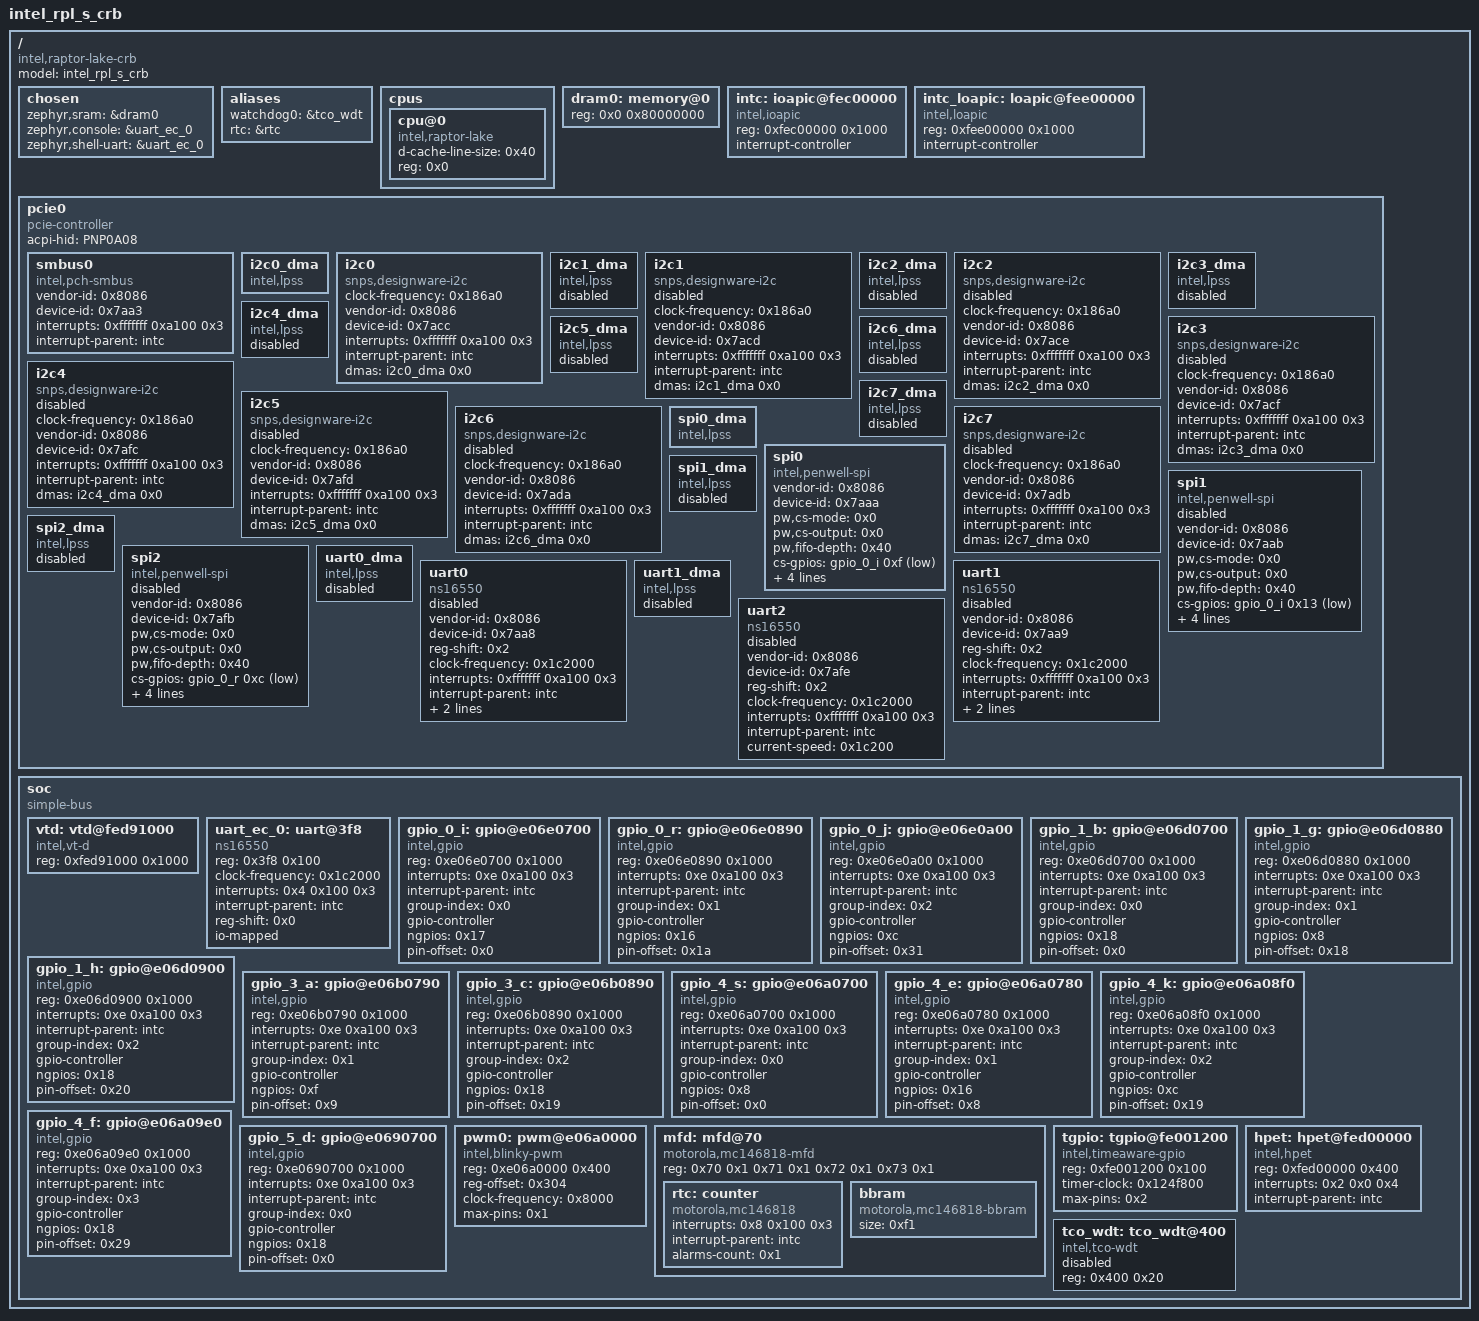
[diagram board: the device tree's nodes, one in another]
/dts-v1/;

/* node '/' defined in zephyr/dts/common/skeleton.dtsi:9 */
/ {
	#address-cells = < 0x1 >;             /* in zephyr/dts/common/skeleton.dtsi:10 */
	#size-cells = < 0x1 >;                /* in zephyr/dts/common/skeleton.dtsi:11 */
	model = "intel_rpl_s_crb";            /* in zephyr/boards/intel/rpl/intel_rpl_s_crb.dts:15 */
	compatible = "intel,raptor-lake-crb"; /* in zephyr/boards/intel/rpl/intel_rpl_s_crb.dts:16 */

	/* node '/chosen' defined in zephyr/dts/common/skeleton.dtsi:13 */
	chosen {
		zephyr,sram = &dram0;           /* in zephyr/boards/intel/rpl/intel_rpl_s_crb.dts:19 */
		zephyr,console = &uart_ec_0;    /* in zephyr/boards/intel/rpl/intel_rpl_s_crb.dts:20 */
		zephyr,shell-uart = &uart_ec_0; /* in zephyr/boards/intel/rpl/intel_rpl_s_crb.dts:21 */
	};

	/* node '/aliases' defined in zephyr/dts/common/skeleton.dtsi:15 */
	aliases {
		watchdog0 = &tco_wdt; /* in zephyr/boards/intel/rpl/intel_rpl_s_crb.dts:25 */
		rtc = &rtc;           /* in zephyr/boards/intel/rpl/intel_rpl_s_crb.dts:26 */
	};

	/* node '/cpus' defined in zephyr/dts/x86/intel/raptor_lake_s.dtsi:13 */
	cpus {
		#address-cells = < 0x1 >; /* in zephyr/dts/x86/intel/raptor_lake_s.dtsi:14 */
		#size-cells = < 0x0 >;    /* in zephyr/dts/x86/intel/raptor_lake_s.dtsi:15 */

		/* node '/cpus/cpu@0' defined in zephyr/dts/x86/intel/raptor_lake_s.dtsi:17 */
		cpu@0 {
			device_type = "cpu";              /* in zephyr/dts/x86/intel/raptor_lake_s.dtsi:18 */
			compatible = "intel,raptor-lake",
			             "intel,x86_64";      /* in zephyr/dts/x86/intel/raptor_lake_s.dtsi:19 */
			d-cache-line-size = < 0x40 >;     /* in zephyr/dts/x86/intel/raptor_lake_s.dtsi:20 */
			reg = < 0x0 >;                    /* in zephyr/dts/x86/intel/raptor_lake_s.dtsi:21 */
		};
	};

	/* node '/memory@0' defined in zephyr/dts/x86/intel/raptor_lake_s.dtsi:25 */
	dram0: memory@0 {
		device_type = "memory";   /* in zephyr/dts/x86/intel/raptor_lake_s.dtsi:26 */
		reg = < 0x0 0x80000000 >; /* in zephyr/dts/x86/intel/raptor_lake_s.dtsi:27 */
	};

	/* node '/ioapic@fec00000' defined in zephyr/dts/x86/intel/raptor_lake_s.dtsi:30 */
	intc: ioapic@fec00000 {
		compatible = "intel,ioapic"; /* in zephyr/dts/x86/intel/raptor_lake_s.dtsi:31 */
		#address-cells = < 0x1 >;    /* in zephyr/dts/x86/intel/raptor_lake_s.dtsi:32 */
		#interrupt-cells = < 0x3 >;  /* in zephyr/dts/x86/intel/raptor_lake_s.dtsi:33 */
		reg = < 0xfec00000 0x1000 >; /* in zephyr/dts/x86/intel/raptor_lake_s.dtsi:34 */
		interrupt-controller;        /* in zephyr/dts/x86/intel/raptor_lake_s.dtsi:35 */
		phandle = < 0x1 >;           /* in zephyr/dts/x86/intel/raptor_lake_s.dtsi:60 */
	};

	/* node '/loapic@fee00000' defined in zephyr/dts/x86/intel/raptor_lake_s.dtsi:38 */
	intc_loapic: loapic@fee00000 {
		compatible = "intel,loapic"; /* in zephyr/dts/x86/intel/raptor_lake_s.dtsi:39 */
		reg = < 0xfee00000 0x1000 >; /* in zephyr/dts/x86/intel/raptor_lake_s.dtsi:40 */
		interrupt-controller;        /* in zephyr/dts/x86/intel/raptor_lake_s.dtsi:41 */
		#interrupt-cells = < 0x3 >;  /* in zephyr/dts/x86/intel/raptor_lake_s.dtsi:42 */
		#address-cells = < 0x1 >;    /* in zephyr/dts/x86/intel/raptor_lake_s.dtsi:43 */
	};

	/* node '/pcie0' defined in zephyr/dts/x86/intel/raptor_lake_s.dtsi:46 */
	pcie0: pcie0 {
		#address-cells = < 0x1 >;       /* in zephyr/dts/x86/intel/raptor_lake_s.dtsi:47 */
		#size-cells = < 0x1 >;          /* in zephyr/dts/x86/intel/raptor_lake_s.dtsi:48 */
		compatible = "pcie-controller"; /* in zephyr/dts/x86/intel/raptor_lake_s.dtsi:49 */
		acpi-hid = "PNP0A08";           /* in zephyr/dts/x86/intel/raptor_lake_s.dtsi:50 */
		ranges;                         /* in zephyr/dts/x86/intel/raptor_lake_s.dtsi:51 */

		/* node '/pcie0/smbus0' defined in zephyr/dts/x86/intel/raptor_lake_s.dtsi:53 */
		smbus0: smbus0 {
			compatible = "intel,pch-smbus";        /* in zephyr/dts/x86/intel/raptor_lake_s.dtsi:54 */
			#address-cells = < 0x1 >;              /* in zephyr/dts/x86/intel/raptor_lake_s.dtsi:55 */
			#size-cells = < 0x0 >;                 /* in zephyr/dts/x86/intel/raptor_lake_s.dtsi:56 */
			vendor-id = < 0x8086 >;                /* in zephyr/dts/x86/intel/raptor_lake_s.dtsi:57 */
			device-id = < 0x7aa3 >;                /* in zephyr/dts/x86/intel/raptor_lake_s.dtsi:58 */
			interrupts = < 0xfffffff 0xa100 0x3 >; /* in zephyr/dts/x86/intel/raptor_lake_s.dtsi:59 */
			interrupt-parent = < &intc >;          /* in zephyr/dts/x86/intel/raptor_lake_s.dtsi:60 */
			status = "okay";                       /* in zephyr/dts/x86/intel/raptor_lake_s.dtsi:62 */
		};

		/* node '/pcie0/i2c0_dma' defined in zephyr/dts/x86/intel/raptor_lake_s.dtsi:65 */
		i2c0_dma: i2c0_dma {
			compatible = "intel,lpss"; /* in zephyr/dts/x86/intel/raptor_lake_s.dtsi:66 */
			#dma-cells = < 0x1 >;      /* in zephyr/dts/x86/intel/raptor_lake_s.dtsi:67 */
			status = "okay";           /* in zephyr/dts/x86/intel/raptor_lake_s.dtsi:68 */
			phandle = < 0x2 >;         /* in zephyr/dts/x86/intel/raptor_lake_s.dtsi:80 */
		};

		/* node '/pcie0/i2c0' defined in zephyr/dts/x86/intel/raptor_lake_s.dtsi:71 */
		i2c0: i2c0 {
			compatible = "snps,designware-i2c";    /* in zephyr/dts/x86/intel/raptor_lake_s.dtsi:72 */
			clock-frequency = < 0x186a0 >;         /* in zephyr/dts/x86/intel/raptor_lake_s.dtsi:73 */
			#address-cells = < 0x1 >;              /* in zephyr/dts/x86/intel/raptor_lake_s.dtsi:74 */
			#size-cells = < 0x0 >;                 /* in zephyr/dts/x86/intel/raptor_lake_s.dtsi:75 */
			vendor-id = < 0x8086 >;                /* in zephyr/dts/x86/intel/raptor_lake_s.dtsi:76 */
			device-id = < 0x7acc >;                /* in zephyr/dts/x86/intel/raptor_lake_s.dtsi:77 */
			interrupts = < 0xfffffff 0xa100 0x3 >; /* in zephyr/dts/x86/intel/raptor_lake_s.dtsi:78 */
			interrupt-parent = < &intc >;          /* in zephyr/dts/x86/intel/raptor_lake_s.dtsi:79 */
			dmas = < &i2c0_dma 0x0 >;              /* in zephyr/dts/x86/intel/raptor_lake_s.dtsi:80 */
			status = "okay";                       /* in zephyr/dts/x86/intel/raptor_lake_s.dtsi:82 */
		};

		/* node '/pcie0/i2c1_dma' defined in zephyr/dts/x86/intel/raptor_lake_s.dtsi:85 */
		i2c1_dma: i2c1_dma {
			compatible = "intel,lpss"; /* in zephyr/dts/x86/intel/raptor_lake_s.dtsi:86 */
			#dma-cells = < 0x1 >;      /* in zephyr/dts/x86/intel/raptor_lake_s.dtsi:87 */
			status = "disabled";       /* in zephyr/dts/x86/intel/raptor_lake_s.dtsi:88 */
			phandle = < 0x3 >;         /* in zephyr/dts/x86/intel/raptor_lake_s.dtsi:100 */
		};

		/* node '/pcie0/i2c1' defined in zephyr/dts/x86/intel/raptor_lake_s.dtsi:91 */
		i2c1: i2c1 {
			compatible = "snps,designware-i2c";    /* in zephyr/dts/x86/intel/raptor_lake_s.dtsi:92 */
			clock-frequency = < 0x186a0 >;         /* in zephyr/dts/x86/intel/raptor_lake_s.dtsi:93 */
			#address-cells = < 0x1 >;              /* in zephyr/dts/x86/intel/raptor_lake_s.dtsi:94 */
			#size-cells = < 0x0 >;                 /* in zephyr/dts/x86/intel/raptor_lake_s.dtsi:95 */
			vendor-id = < 0x8086 >;                /* in zephyr/dts/x86/intel/raptor_lake_s.dtsi:96 */
			device-id = < 0x7acd >;                /* in zephyr/dts/x86/intel/raptor_lake_s.dtsi:97 */
			interrupts = < 0xfffffff 0xa100 0x3 >; /* in zephyr/dts/x86/intel/raptor_lake_s.dtsi:98 */
			interrupt-parent = < &intc >;          /* in zephyr/dts/x86/intel/raptor_lake_s.dtsi:99 */
			dmas = < &i2c1_dma 0x0 >;              /* in zephyr/dts/x86/intel/raptor_lake_s.dtsi:100 */
			status = "disabled";                   /* in zephyr/dts/x86/intel/raptor_lake_s.dtsi:102 */
		};

		/* node '/pcie0/i2c2_dma' defined in zephyr/dts/x86/intel/raptor_lake_s.dtsi:105 */
		i2c2_dma: i2c2_dma {
			compatible = "intel,lpss"; /* in zephyr/dts/x86/intel/raptor_lake_s.dtsi:106 */
			#dma-cells = < 0x1 >;      /* in zephyr/dts/x86/intel/raptor_lake_s.dtsi:107 */
			status = "disabled";       /* in zephyr/dts/x86/intel/raptor_lake_s.dtsi:108 */
			phandle = < 0x4 >;         /* in zephyr/dts/x86/intel/raptor_lake_s.dtsi:122 */
		};

		/* node '/pcie0/i2c2' defined in zephyr/dts/x86/intel/raptor_lake_s.dtsi:111 */
		i2c2: i2c2 {
			compatible = "snps,designware-i2c";    /* in zephyr/dts/x86/intel/raptor_lake_s.dtsi:112 */
			clock-frequency = < 0x186a0 >;         /* in zephyr/dts/x86/intel/raptor_lake_s.dtsi:113 */
			#address-cells = < 0x1 >;              /* in zephyr/dts/x86/intel/raptor_lake_s.dtsi:116 */
			#size-cells = < 0x0 >;                 /* in zephyr/dts/x86/intel/raptor_lake_s.dtsi:117 */
			vendor-id = < 0x8086 >;                /* in zephyr/dts/x86/intel/raptor_lake_s.dtsi:118 */
			device-id = < 0x7ace >;                /* in zephyr/dts/x86/intel/raptor_lake_s.dtsi:119 */
			interrupts = < 0xfffffff 0xa100 0x3 >; /* in zephyr/dts/x86/intel/raptor_lake_s.dtsi:120 */
			interrupt-parent = < &intc >;          /* in zephyr/dts/x86/intel/raptor_lake_s.dtsi:121 */
			dmas = < &i2c2_dma 0x0 >;              /* in zephyr/dts/x86/intel/raptor_lake_s.dtsi:122 */
			status = "disabled";                   /* in zephyr/dts/x86/intel/raptor_lake_s.dtsi:124 */
		};

		/* node '/pcie0/i2c3_dma' defined in zephyr/dts/x86/intel/raptor_lake_s.dtsi:127 */
		i2c3_dma: i2c3_dma {
			compatible = "intel,lpss"; /* in zephyr/dts/x86/intel/raptor_lake_s.dtsi:128 */
			#dma-cells = < 0x1 >;      /* in zephyr/dts/x86/intel/raptor_lake_s.dtsi:129 */
			status = "disabled";       /* in zephyr/dts/x86/intel/raptor_lake_s.dtsi:130 */
			phandle = < 0x5 >;         /* in zephyr/dts/x86/intel/raptor_lake_s.dtsi:142 */
		};

		/* node '/pcie0/i2c3' defined in zephyr/dts/x86/intel/raptor_lake_s.dtsi:133 */
		i2c3: i2c3 {
			compatible = "snps,designware-i2c";    /* in zephyr/dts/x86/intel/raptor_lake_s.dtsi:134 */
			clock-frequency = < 0x186a0 >;         /* in zephyr/dts/x86/intel/raptor_lake_s.dtsi:135 */
			#address-cells = < 0x1 >;              /* in zephyr/dts/x86/intel/raptor_lake_s.dtsi:136 */
			#size-cells = < 0x0 >;                 /* in zephyr/dts/x86/intel/raptor_lake_s.dtsi:137 */
			vendor-id = < 0x8086 >;                /* in zephyr/dts/x86/intel/raptor_lake_s.dtsi:138 */
			device-id = < 0x7acf >;                /* in zephyr/dts/x86/intel/raptor_lake_s.dtsi:139 */
			interrupts = < 0xfffffff 0xa100 0x3 >; /* in zephyr/dts/x86/intel/raptor_lake_s.dtsi:140 */
			interrupt-parent = < &intc >;          /* in zephyr/dts/x86/intel/raptor_lake_s.dtsi:141 */
			dmas = < &i2c3_dma 0x0 >;              /* in zephyr/dts/x86/intel/raptor_lake_s.dtsi:142 */
			status = "disabled";                   /* in zephyr/dts/x86/intel/raptor_lake_s.dtsi:144 */
		};

		/* node '/pcie0/i2c4_dma' defined in zephyr/dts/x86/intel/raptor_lake_s.dtsi:147 */
		i2c4_dma: i2c4_dma {
			compatible = "intel,lpss"; /* in zephyr/dts/x86/intel/raptor_lake_s.dtsi:148 */
			#dma-cells = < 0x1 >;      /* in zephyr/dts/x86/intel/raptor_lake_s.dtsi:149 */
			status = "disabled";       /* in zephyr/dts/x86/intel/raptor_lake_s.dtsi:150 */
			phandle = < 0x6 >;         /* in zephyr/dts/x86/intel/raptor_lake_s.dtsi:162 */
		};

		/* node '/pcie0/i2c4' defined in zephyr/dts/x86/intel/raptor_lake_s.dtsi:153 */
		i2c4: i2c4 {
			compatible = "snps,designware-i2c";    /* in zephyr/dts/x86/intel/raptor_lake_s.dtsi:154 */
			clock-frequency = < 0x186a0 >;         /* in zephyr/dts/x86/intel/raptor_lake_s.dtsi:155 */
			#address-cells = < 0x1 >;              /* in zephyr/dts/x86/intel/raptor_lake_s.dtsi:156 */
			#size-cells = < 0x0 >;                 /* in zephyr/dts/x86/intel/raptor_lake_s.dtsi:157 */
			vendor-id = < 0x8086 >;                /* in zephyr/dts/x86/intel/raptor_lake_s.dtsi:158 */
			device-id = < 0x7afc >;                /* in zephyr/dts/x86/intel/raptor_lake_s.dtsi:159 */
			interrupts = < 0xfffffff 0xa100 0x3 >; /* in zephyr/dts/x86/intel/raptor_lake_s.dtsi:160 */
			interrupt-parent = < &intc >;          /* in zephyr/dts/x86/intel/raptor_lake_s.dtsi:161 */
			dmas = < &i2c4_dma 0x0 >;              /* in zephyr/dts/x86/intel/raptor_lake_s.dtsi:162 */
			status = "disabled";                   /* in zephyr/dts/x86/intel/raptor_lake_s.dtsi:164 */
		};

		/* node '/pcie0/i2c5_dma' defined in zephyr/dts/x86/intel/raptor_lake_s.dtsi:167 */
		i2c5_dma: i2c5_dma {
			compatible = "intel,lpss"; /* in zephyr/dts/x86/intel/raptor_lake_s.dtsi:168 */
			#dma-cells = < 0x1 >;      /* in zephyr/dts/x86/intel/raptor_lake_s.dtsi:169 */
			status = "disabled";       /* in zephyr/dts/x86/intel/raptor_lake_s.dtsi:170 */
			phandle = < 0x7 >;         /* in zephyr/dts/x86/intel/raptor_lake_s.dtsi:182 */
		};

		/* node '/pcie0/i2c5' defined in zephyr/dts/x86/intel/raptor_lake_s.dtsi:173 */
		i2c5: i2c5 {
			compatible = "snps,designware-i2c";    /* in zephyr/dts/x86/intel/raptor_lake_s.dtsi:174 */
			clock-frequency = < 0x186a0 >;         /* in zephyr/dts/x86/intel/raptor_lake_s.dtsi:175 */
			#address-cells = < 0x1 >;              /* in zephyr/dts/x86/intel/raptor_lake_s.dtsi:176 */
			#size-cells = < 0x0 >;                 /* in zephyr/dts/x86/intel/raptor_lake_s.dtsi:177 */
			vendor-id = < 0x8086 >;                /* in zephyr/dts/x86/intel/raptor_lake_s.dtsi:178 */
			device-id = < 0x7afd >;                /* in zephyr/dts/x86/intel/raptor_lake_s.dtsi:179 */
			interrupts = < 0xfffffff 0xa100 0x3 >; /* in zephyr/dts/x86/intel/raptor_lake_s.dtsi:180 */
			interrupt-parent = < &intc >;          /* in zephyr/dts/x86/intel/raptor_lake_s.dtsi:181 */
			dmas = < &i2c5_dma 0x0 >;              /* in zephyr/dts/x86/intel/raptor_lake_s.dtsi:182 */
			status = "disabled";                   /* in zephyr/dts/x86/intel/raptor_lake_s.dtsi:184 */
		};

		/* node '/pcie0/i2c6_dma' defined in zephyr/dts/x86/intel/raptor_lake_s.dtsi:187 */
		i2c6_dma: i2c6_dma {
			compatible = "intel,lpss"; /* in zephyr/dts/x86/intel/raptor_lake_s.dtsi:188 */
			#dma-cells = < 0x1 >;      /* in zephyr/dts/x86/intel/raptor_lake_s.dtsi:189 */
			status = "disabled";       /* in zephyr/dts/x86/intel/raptor_lake_s.dtsi:190 */
			phandle = < 0x8 >;         /* in zephyr/dts/x86/intel/raptor_lake_s.dtsi:202 */
		};

		/* node '/pcie0/i2c6' defined in zephyr/dts/x86/intel/raptor_lake_s.dtsi:193 */
		i2c6: i2c6 {
			compatible = "snps,designware-i2c";    /* in zephyr/dts/x86/intel/raptor_lake_s.dtsi:194 */
			clock-frequency = < 0x186a0 >;         /* in zephyr/dts/x86/intel/raptor_lake_s.dtsi:195 */
			#address-cells = < 0x1 >;              /* in zephyr/dts/x86/intel/raptor_lake_s.dtsi:196 */
			#size-cells = < 0x0 >;                 /* in zephyr/dts/x86/intel/raptor_lake_s.dtsi:197 */
			vendor-id = < 0x8086 >;                /* in zephyr/dts/x86/intel/raptor_lake_s.dtsi:198 */
			device-id = < 0x7ada >;                /* in zephyr/dts/x86/intel/raptor_lake_s.dtsi:199 */
			interrupts = < 0xfffffff 0xa100 0x3 >; /* in zephyr/dts/x86/intel/raptor_lake_s.dtsi:200 */
			interrupt-parent = < &intc >;          /* in zephyr/dts/x86/intel/raptor_lake_s.dtsi:201 */
			dmas = < &i2c6_dma 0x0 >;              /* in zephyr/dts/x86/intel/raptor_lake_s.dtsi:202 */
			status = "disabled";                   /* in zephyr/dts/x86/intel/raptor_lake_s.dtsi:204 */
		};

		/* node '/pcie0/i2c7_dma' defined in zephyr/dts/x86/intel/raptor_lake_s.dtsi:207 */
		i2c7_dma: i2c7_dma {
			compatible = "intel,lpss"; /* in zephyr/dts/x86/intel/raptor_lake_s.dtsi:208 */
			#dma-cells = < 0x1 >;      /* in zephyr/dts/x86/intel/raptor_lake_s.dtsi:209 */
			status = "disabled";       /* in zephyr/dts/x86/intel/raptor_lake_s.dtsi:210 */
			phandle = < 0x9 >;         /* in zephyr/dts/x86/intel/raptor_lake_s.dtsi:222 */
		};

		/* node '/pcie0/i2c7' defined in zephyr/dts/x86/intel/raptor_lake_s.dtsi:213 */
		i2c7: i2c7 {
			compatible = "snps,designware-i2c";    /* in zephyr/dts/x86/intel/raptor_lake_s.dtsi:214 */
			clock-frequency = < 0x186a0 >;         /* in zephyr/dts/x86/intel/raptor_lake_s.dtsi:215 */
			#address-cells = < 0x1 >;              /* in zephyr/dts/x86/intel/raptor_lake_s.dtsi:216 */
			#size-cells = < 0x0 >;                 /* in zephyr/dts/x86/intel/raptor_lake_s.dtsi:217 */
			vendor-id = < 0x8086 >;                /* in zephyr/dts/x86/intel/raptor_lake_s.dtsi:218 */
			device-id = < 0x7adb >;                /* in zephyr/dts/x86/intel/raptor_lake_s.dtsi:219 */
			interrupts = < 0xfffffff 0xa100 0x3 >; /* in zephyr/dts/x86/intel/raptor_lake_s.dtsi:220 */
			interrupt-parent = < &intc >;          /* in zephyr/dts/x86/intel/raptor_lake_s.dtsi:221 */
			dmas = < &i2c7_dma 0x0 >;              /* in zephyr/dts/x86/intel/raptor_lake_s.dtsi:222 */
			status = "disabled";                   /* in zephyr/dts/x86/intel/raptor_lake_s.dtsi:224 */
		};

		/* node '/pcie0/spi0_dma' defined in zephyr/dts/x86/intel/raptor_lake_s.dtsi:227 */
		spi0_dma: spi0_dma {
			compatible = "intel,lpss"; /* in zephyr/dts/x86/intel/raptor_lake_s.dtsi:228 */
			#dma-cells = < 0x1 >;      /* in zephyr/dts/x86/intel/raptor_lake_s.dtsi:229 */
			status = "okay";           /* in zephyr/dts/x86/intel/raptor_lake_s.dtsi:230 */
			phandle = < 0xb >;         /* in zephyr/dts/x86/intel/raptor_lake_s.dtsi:246 */
		};

		/* node '/pcie0/spi0' defined in zephyr/dts/x86/intel/raptor_lake_s.dtsi:233 */
		spi0: spi0 {
			compatible = "intel,penwell-spi";      /* in zephyr/dts/x86/intel/raptor_lake_s.dtsi:234 */
			vendor-id = < 0x8086 >;                /* in zephyr/dts/x86/intel/raptor_lake_s.dtsi:235 */
			device-id = < 0x7aaa >;                /* in zephyr/dts/x86/intel/raptor_lake_s.dtsi:236 */
			#address-cells = < 0x1 >;              /* in zephyr/dts/x86/intel/raptor_lake_s.dtsi:237 */
			#size-cells = < 0x0 >;                 /* in zephyr/dts/x86/intel/raptor_lake_s.dtsi:238 */
			pw,cs-mode = < 0x0 >;                  /* in zephyr/dts/x86/intel/raptor_lake_s.dtsi:239 */
			pw,cs-output = < 0x0 >;                /* in zephyr/dts/x86/intel/raptor_lake_s.dtsi:240 */
			pw,fifo-depth = < 0x40 >;              /* in zephyr/dts/x86/intel/raptor_lake_s.dtsi:241 */
			cs-gpios = < &gpio_0_i 0xf 0x1 >;      /* in zephyr/dts/x86/intel/raptor_lake_s.dtsi:242 */
			clock-frequency = < 0x5f5e100 >;       /* in zephyr/dts/x86/intel/raptor_lake_s.dtsi:243 */
			interrupts = < 0xfffffff 0xa100 0x3 >; /* in zephyr/dts/x86/intel/raptor_lake_s.dtsi:244 */
			interrupt-parent = < &intc >;          /* in zephyr/dts/x86/intel/raptor_lake_s.dtsi:245 */
			dmas = < &spi0_dma 0x0 >;              /* in zephyr/dts/x86/intel/raptor_lake_s.dtsi:246 */
			status = "okay";                       /* in zephyr/dts/x86/intel/raptor_lake_s.dtsi:247 */
		};

		/* node '/pcie0/spi1_dma' defined in zephyr/dts/x86/intel/raptor_lake_s.dtsi:250 */
		spi1_dma: spi1_dma {
			compatible = "intel,lpss"; /* in zephyr/dts/x86/intel/raptor_lake_s.dtsi:251 */
			#dma-cells = < 0x1 >;      /* in zephyr/dts/x86/intel/raptor_lake_s.dtsi:252 */
			status = "disabled";       /* in zephyr/dts/x86/intel/raptor_lake_s.dtsi:253 */
			phandle = < 0xc >;         /* in zephyr/dts/x86/intel/raptor_lake_s.dtsi:269 */
		};

		/* node '/pcie0/spi1' defined in zephyr/dts/x86/intel/raptor_lake_s.dtsi:256 */
		spi1: spi1 {
			compatible = "intel,penwell-spi";      /* in zephyr/dts/x86/intel/raptor_lake_s.dtsi:257 */
			vendor-id = < 0x8086 >;                /* in zephyr/dts/x86/intel/raptor_lake_s.dtsi:258 */
			device-id = < 0x7aab >;                /* in zephyr/dts/x86/intel/raptor_lake_s.dtsi:259 */
			#address-cells = < 0x1 >;              /* in zephyr/dts/x86/intel/raptor_lake_s.dtsi:260 */
			#size-cells = < 0x0 >;                 /* in zephyr/dts/x86/intel/raptor_lake_s.dtsi:261 */
			pw,cs-mode = < 0x0 >;                  /* in zephyr/dts/x86/intel/raptor_lake_s.dtsi:262 */
			pw,cs-output = < 0x0 >;                /* in zephyr/dts/x86/intel/raptor_lake_s.dtsi:263 */
			pw,fifo-depth = < 0x40 >;              /* in zephyr/dts/x86/intel/raptor_lake_s.dtsi:264 */
			cs-gpios = < &gpio_0_i 0x13 0x1 >;     /* in zephyr/dts/x86/intel/raptor_lake_s.dtsi:265 */
			clock-frequency = < 0x5f5e100 >;       /* in zephyr/dts/x86/intel/raptor_lake_s.dtsi:266 */
			interrupts = < 0xfffffff 0xa100 0x3 >; /* in zephyr/dts/x86/intel/raptor_lake_s.dtsi:267 */
			interrupt-parent = < &intc >;          /* in zephyr/dts/x86/intel/raptor_lake_s.dtsi:268 */
			dmas = < &spi1_dma 0x0 >;              /* in zephyr/dts/x86/intel/raptor_lake_s.dtsi:269 */
			status = "disabled";                   /* in zephyr/dts/x86/intel/raptor_lake_s.dtsi:270 */
		};

		/* node '/pcie0/spi2_dma' defined in zephyr/dts/x86/intel/raptor_lake_s.dtsi:273 */
		spi2_dma: spi2_dma {
			compatible = "intel,lpss"; /* in zephyr/dts/x86/intel/raptor_lake_s.dtsi:274 */
			#dma-cells = < 0x1 >;      /* in zephyr/dts/x86/intel/raptor_lake_s.dtsi:275 */
			status = "disabled";       /* in zephyr/dts/x86/intel/raptor_lake_s.dtsi:276 */
			phandle = < 0xe >;         /* in zephyr/dts/x86/intel/raptor_lake_s.dtsi:292 */
		};

		/* node '/pcie0/spi2' defined in zephyr/dts/x86/intel/raptor_lake_s.dtsi:279 */
		spi2: spi2 {
			compatible = "intel,penwell-spi";      /* in zephyr/dts/x86/intel/raptor_lake_s.dtsi:280 */
			vendor-id = < 0x8086 >;                /* in zephyr/dts/x86/intel/raptor_lake_s.dtsi:281 */
			device-id = < 0x7afb >;                /* in zephyr/dts/x86/intel/raptor_lake_s.dtsi:282 */
			#address-cells = < 0x1 >;              /* in zephyr/dts/x86/intel/raptor_lake_s.dtsi:283 */
			#size-cells = < 0x0 >;                 /* in zephyr/dts/x86/intel/raptor_lake_s.dtsi:284 */
			pw,cs-mode = < 0x0 >;                  /* in zephyr/dts/x86/intel/raptor_lake_s.dtsi:285 */
			pw,cs-output = < 0x0 >;                /* in zephyr/dts/x86/intel/raptor_lake_s.dtsi:286 */
			pw,fifo-depth = < 0x40 >;              /* in zephyr/dts/x86/intel/raptor_lake_s.dtsi:287 */
			cs-gpios = < &gpio_0_r 0xc 0x1 >;      /* in zephyr/dts/x86/intel/raptor_lake_s.dtsi:288 */
			clock-frequency = < 0x5f5e100 >;       /* in zephyr/dts/x86/intel/raptor_lake_s.dtsi:289 */
			interrupts = < 0xfffffff 0xa100 0x3 >; /* in zephyr/dts/x86/intel/raptor_lake_s.dtsi:290 */
			interrupt-parent = < &intc >;          /* in zephyr/dts/x86/intel/raptor_lake_s.dtsi:291 */
			dmas = < &spi2_dma 0x0 >;              /* in zephyr/dts/x86/intel/raptor_lake_s.dtsi:292 */
			status = "disabled";                   /* in zephyr/dts/x86/intel/raptor_lake_s.dtsi:293 */
		};

		/* node '/pcie0/uart0_dma' defined in zephyr/dts/x86/intel/raptor_lake_s.dtsi:296 */
		uart0_dma: uart0_dma {
			compatible = "intel,lpss"; /* in zephyr/dts/x86/intel/raptor_lake_s.dtsi:297 */
			#dma-cells = < 0x1 >;      /* in zephyr/dts/x86/intel/raptor_lake_s.dtsi:298 */
			status = "disabled";       /* in zephyr/dts/x86/intel/raptor_lake_s.dtsi:299 */
			phandle = < 0xf >;         /* in zephyr/dts/x86/intel/raptor_lake_s.dtsi:311 */
		};

		/* node '/pcie0/uart0' defined in zephyr/dts/x86/intel/raptor_lake_s.dtsi:302 */
		uart0: uart0 {
			compatible = "ns16550";                /* in zephyr/dts/x86/intel/raptor_lake_s.dtsi:303 */
			vendor-id = < 0x8086 >;                /* in zephyr/dts/x86/intel/raptor_lake_s.dtsi:304 */
			device-id = < 0x7aa8 >;                /* in zephyr/dts/x86/intel/raptor_lake_s.dtsi:305 */
			reg-shift = < 0x2 >;                   /* in zephyr/dts/x86/intel/raptor_lake_s.dtsi:306 */
			clock-frequency = < 0x1c2000 >;        /* in zephyr/dts/x86/intel/raptor_lake_s.dtsi:307 */
			interrupts = < 0xfffffff 0xa100 0x3 >; /* in zephyr/dts/x86/intel/raptor_lake_s.dtsi:308 */
			interrupt-parent = < &intc >;          /* in zephyr/dts/x86/intel/raptor_lake_s.dtsi:309 */
			current-speed = < 0x1c200 >;           /* in zephyr/dts/x86/intel/raptor_lake_s.dtsi:310 */
			dmas = < &uart0_dma 0x0 >,
			       < &uart0_dma 0x1 >;             /* in zephyr/dts/x86/intel/raptor_lake_s.dtsi:311 */
			dma-names = "tx",
			            "rx";                      /* in zephyr/dts/x86/intel/raptor_lake_s.dtsi:312 */
			status = "disabled";                   /* in zephyr/dts/x86/intel/raptor_lake_s.dtsi:313 */
		};

		/* node '/pcie0/uart1_dma' defined in zephyr/dts/x86/intel/raptor_lake_s.dtsi:316 */
		uart1_dma: uart1_dma {
			compatible = "intel,lpss"; /* in zephyr/dts/x86/intel/raptor_lake_s.dtsi:317 */
			#dma-cells = < 0x1 >;      /* in zephyr/dts/x86/intel/raptor_lake_s.dtsi:318 */
			status = "disabled";       /* in zephyr/dts/x86/intel/raptor_lake_s.dtsi:319 */
			phandle = < 0x10 >;        /* in zephyr/dts/x86/intel/raptor_lake_s.dtsi:331 */
		};

		/* node '/pcie0/uart1' defined in zephyr/dts/x86/intel/raptor_lake_s.dtsi:322 */
		uart1: uart1 {
			compatible = "ns16550";                /* in zephyr/dts/x86/intel/raptor_lake_s.dtsi:323 */
			vendor-id = < 0x8086 >;                /* in zephyr/dts/x86/intel/raptor_lake_s.dtsi:324 */
			device-id = < 0x7aa9 >;                /* in zephyr/dts/x86/intel/raptor_lake_s.dtsi:325 */
			reg-shift = < 0x2 >;                   /* in zephyr/dts/x86/intel/raptor_lake_s.dtsi:326 */
			clock-frequency = < 0x1c2000 >;        /* in zephyr/dts/x86/intel/raptor_lake_s.dtsi:327 */
			interrupts = < 0xfffffff 0xa100 0x3 >; /* in zephyr/dts/x86/intel/raptor_lake_s.dtsi:328 */
			interrupt-parent = < &intc >;          /* in zephyr/dts/x86/intel/raptor_lake_s.dtsi:329 */
			current-speed = < 0x1c200 >;           /* in zephyr/dts/x86/intel/raptor_lake_s.dtsi:330 */
			dmas = < &uart1_dma 0x0 >,
			       < &uart1_dma 0x1 >;             /* in zephyr/dts/x86/intel/raptor_lake_s.dtsi:331 */
			dma-names = "tx",
			            "rx";                      /* in zephyr/dts/x86/intel/raptor_lake_s.dtsi:332 */
			status = "disabled";                   /* in zephyr/dts/x86/intel/raptor_lake_s.dtsi:333 */
		};

		/* node '/pcie0/uart2' defined in zephyr/dts/x86/intel/raptor_lake_s.dtsi:336 */
		uart2: uart2 {
			compatible = "ns16550";                /* in zephyr/dts/x86/intel/raptor_lake_s.dtsi:337 */
			vendor-id = < 0x8086 >;                /* in zephyr/dts/x86/intel/raptor_lake_s.dtsi:338 */
			device-id = < 0x7afe >;                /* in zephyr/dts/x86/intel/raptor_lake_s.dtsi:339 */
			reg-shift = < 0x2 >;                   /* in zephyr/dts/x86/intel/raptor_lake_s.dtsi:340 */
			clock-frequency = < 0x1c2000 >;        /* in zephyr/dts/x86/intel/raptor_lake_s.dtsi:341 */
			interrupts = < 0xfffffff 0xa100 0x3 >; /* in zephyr/dts/x86/intel/raptor_lake_s.dtsi:342 */
			interrupt-parent = < &intc >;          /* in zephyr/dts/x86/intel/raptor_lake_s.dtsi:343 */
			current-speed = < 0x1c200 >;           /* in zephyr/dts/x86/intel/raptor_lake_s.dtsi:344 */
			status = "disabled";                   /* in zephyr/dts/x86/intel/raptor_lake_s.dtsi:345 */
		};
	};

	/* node '/soc' defined in zephyr/dts/x86/intel/raptor_lake_s.dtsi:349 */
	soc {
		#address-cells = < 0x1 >;  /* in zephyr/dts/x86/intel/raptor_lake_s.dtsi:350 */
		#size-cells = < 0x1 >;     /* in zephyr/dts/x86/intel/raptor_lake_s.dtsi:351 */
		compatible = "simple-bus"; /* in zephyr/dts/x86/intel/raptor_lake_s.dtsi:352 */
		ranges;                    /* in zephyr/dts/x86/intel/raptor_lake_s.dtsi:353 */

		/* node '/soc/vtd@fed91000' defined in zephyr/dts/x86/intel/raptor_lake_s.dtsi:355 */
		vtd: vtd@fed91000 {
			compatible = "intel,vt-d";   /* in zephyr/dts/x86/intel/raptor_lake_s.dtsi:356 */
			reg = < 0xfed91000 0x1000 >; /* in zephyr/dts/x86/intel/raptor_lake_s.dtsi:357 */
			status = "okay";             /* in zephyr/dts/x86/intel/raptor_lake_s.dtsi:359 */
		};

		/* node '/soc/uart@3f8' defined in zephyr/dts/x86/intel/raptor_lake_s.dtsi:362 */
		uart_ec_0: uart@3f8 {
			compatible = "ns16550";         /* in zephyr/dts/x86/intel/raptor_lake_s.dtsi:363 */
			reg = < 0x3f8 0x100 >;          /* in zephyr/dts/x86/intel/raptor_lake_s.dtsi:364 */
			clock-frequency = < 0x1c2000 >; /* in zephyr/dts/x86/intel/raptor_lake_s.dtsi:366 */
			interrupts = < 0x4 0x100 0x3 >; /* in zephyr/dts/x86/intel/raptor_lake_s.dtsi:367 */
			interrupt-parent = < &intc >;   /* in zephyr/dts/x86/intel/raptor_lake_s.dtsi:368 */
			reg-shift = < 0x0 >;            /* in zephyr/dts/x86/intel/raptor_lake_s.dtsi:369 */
			io-mapped;                      /* in zephyr/dts/x86/intel/raptor_lake_s.dtsi:370 */
			status = "okay";                /* in zephyr/dts/x86/intel/raptor_lake_s.dtsi:371 */
		};

		/* node '/soc/gpio@e06e0700' defined in zephyr/dts/x86/intel/raptor_lake_s.dtsi:374 */
		gpio_0_i: gpio@e06e0700 {
			compatible = "intel,gpio";       /* in zephyr/dts/x86/intel/raptor_lake_s.dtsi:375 */
			reg = < 0xe06e0700 0x1000 >;     /* in zephyr/dts/x86/intel/raptor_lake_s.dtsi:376 */
			interrupts = < 0xe 0xa100 0x3 >; /* in zephyr/dts/x86/intel/raptor_lake_s.dtsi:377 */
			interrupt-parent = < &intc >;    /* in zephyr/dts/x86/intel/raptor_lake_s.dtsi:378 */
			group-index = < 0x0 >;           /* in zephyr/dts/x86/intel/raptor_lake_s.dtsi:379 */
			gpio-controller;                 /* in zephyr/dts/x86/intel/raptor_lake_s.dtsi:380 */
			#gpio-cells = < 0x2 >;           /* in zephyr/dts/x86/intel/raptor_lake_s.dtsi:381 */
			ngpios = < 0x17 >;               /* in zephyr/dts/x86/intel/raptor_lake_s.dtsi:382 */
			pin-offset = < 0x0 >;            /* in zephyr/dts/x86/intel/raptor_lake_s.dtsi:383 */
			status = "okay";                 /* in zephyr/dts/x86/intel/raptor_lake_s.dtsi:385 */
			phandle = < 0xa >;               /* in zephyr/dts/x86/intel/raptor_lake_s.dtsi:242 */
		};

		/* node '/soc/gpio@e06e0890' defined in zephyr/dts/x86/intel/raptor_lake_s.dtsi:388 */
		gpio_0_r: gpio@e06e0890 {
			compatible = "intel,gpio";       /* in zephyr/dts/x86/intel/raptor_lake_s.dtsi:389 */
			reg = < 0xe06e0890 0x1000 >;     /* in zephyr/dts/x86/intel/raptor_lake_s.dtsi:390 */
			interrupts = < 0xe 0xa100 0x3 >; /* in zephyr/dts/x86/intel/raptor_lake_s.dtsi:391 */
			interrupt-parent = < &intc >;    /* in zephyr/dts/x86/intel/raptor_lake_s.dtsi:392 */
			group-index = < 0x1 >;           /* in zephyr/dts/x86/intel/raptor_lake_s.dtsi:393 */
			gpio-controller;                 /* in zephyr/dts/x86/intel/raptor_lake_s.dtsi:394 */
			#gpio-cells = < 0x2 >;           /* in zephyr/dts/x86/intel/raptor_lake_s.dtsi:395 */
			ngpios = < 0x16 >;               /* in zephyr/dts/x86/intel/raptor_lake_s.dtsi:396 */
			pin-offset = < 0x1a >;           /* in zephyr/dts/x86/intel/raptor_lake_s.dtsi:397 */
			status = "okay";                 /* in zephyr/dts/x86/intel/raptor_lake_s.dtsi:399 */
			phandle = < 0xd >;               /* in zephyr/dts/x86/intel/raptor_lake_s.dtsi:288 */
		};

		/* node '/soc/gpio@e06e0a00' defined in zephyr/dts/x86/intel/raptor_lake_s.dtsi:402 */
		gpio_0_j: gpio@e06e0a00 {
			compatible = "intel,gpio";       /* in zephyr/dts/x86/intel/raptor_lake_s.dtsi:403 */
			reg = < 0xe06e0a00 0x1000 >;     /* in zephyr/dts/x86/intel/raptor_lake_s.dtsi:404 */
			interrupts = < 0xe 0xa100 0x3 >; /* in zephyr/dts/x86/intel/raptor_lake_s.dtsi:405 */
			interrupt-parent = < &intc >;    /* in zephyr/dts/x86/intel/raptor_lake_s.dtsi:406 */
			group-index = < 0x2 >;           /* in zephyr/dts/x86/intel/raptor_lake_s.dtsi:407 */
			gpio-controller;                 /* in zephyr/dts/x86/intel/raptor_lake_s.dtsi:408 */
			#gpio-cells = < 0x2 >;           /* in zephyr/dts/x86/intel/raptor_lake_s.dtsi:409 */
			ngpios = < 0xc >;                /* in zephyr/dts/x86/intel/raptor_lake_s.dtsi:410 */
			pin-offset = < 0x31 >;           /* in zephyr/dts/x86/intel/raptor_lake_s.dtsi:411 */
			status = "okay";                 /* in zephyr/dts/x86/intel/raptor_lake_s.dtsi:413 */
		};

		/* node '/soc/gpio@e06d0700' defined in zephyr/dts/x86/intel/raptor_lake_s.dtsi:416 */
		gpio_1_b: gpio@e06d0700 {
			compatible = "intel,gpio";       /* in zephyr/dts/x86/intel/raptor_lake_s.dtsi:417 */
			reg = < 0xe06d0700 0x1000 >;     /* in zephyr/dts/x86/intel/raptor_lake_s.dtsi:418 */
			interrupts = < 0xe 0xa100 0x3 >; /* in zephyr/dts/x86/intel/raptor_lake_s.dtsi:419 */
			interrupt-parent = < &intc >;    /* in zephyr/dts/x86/intel/raptor_lake_s.dtsi:420 */
			group-index = < 0x0 >;           /* in zephyr/dts/x86/intel/raptor_lake_s.dtsi:421 */
			gpio-controller;                 /* in zephyr/dts/x86/intel/raptor_lake_s.dtsi:422 */
			#gpio-cells = < 0x2 >;           /* in zephyr/dts/x86/intel/raptor_lake_s.dtsi:423 */
			ngpios = < 0x18 >;               /* in zephyr/dts/x86/intel/raptor_lake_s.dtsi:424 */
			pin-offset = < 0x0 >;            /* in zephyr/dts/x86/intel/raptor_lake_s.dtsi:425 */
			status = "okay";                 /* in zephyr/dts/x86/intel/raptor_lake_s.dtsi:427 */
		};

		/* node '/soc/gpio@e06d0880' defined in zephyr/dts/x86/intel/raptor_lake_s.dtsi:430 */
		gpio_1_g: gpio@e06d0880 {
			compatible = "intel,gpio";       /* in zephyr/dts/x86/intel/raptor_lake_s.dtsi:431 */
			reg = < 0xe06d0880 0x1000 >;     /* in zephyr/dts/x86/intel/raptor_lake_s.dtsi:432 */
			interrupts = < 0xe 0xa100 0x3 >; /* in zephyr/dts/x86/intel/raptor_lake_s.dtsi:433 */
			interrupt-parent = < &intc >;    /* in zephyr/dts/x86/intel/raptor_lake_s.dtsi:434 */
			group-index = < 0x1 >;           /* in zephyr/dts/x86/intel/raptor_lake_s.dtsi:435 */
			gpio-controller;                 /* in zephyr/dts/x86/intel/raptor_lake_s.dtsi:436 */
			#gpio-cells = < 0x2 >;           /* in zephyr/dts/x86/intel/raptor_lake_s.dtsi:437 */
			ngpios = < 0x8 >;                /* in zephyr/dts/x86/intel/raptor_lake_s.dtsi:438 */
			pin-offset = < 0x18 >;           /* in zephyr/dts/x86/intel/raptor_lake_s.dtsi:439 */
			status = "okay";                 /* in zephyr/dts/x86/intel/raptor_lake_s.dtsi:441 */
		};

		/* node '/soc/gpio@e06d0900' defined in zephyr/dts/x86/intel/raptor_lake_s.dtsi:444 */
		gpio_1_h: gpio@e06d0900 {
			compatible = "intel,gpio";       /* in zephyr/dts/x86/intel/raptor_lake_s.dtsi:445 */
			reg = < 0xe06d0900 0x1000 >;     /* in zephyr/dts/x86/intel/raptor_lake_s.dtsi:446 */
			interrupts = < 0xe 0xa100 0x3 >; /* in zephyr/dts/x86/intel/raptor_lake_s.dtsi:447 */
			interrupt-parent = < &intc >;    /* in zephyr/dts/x86/intel/raptor_lake_s.dtsi:448 */
			group-index = < 0x2 >;           /* in zephyr/dts/x86/intel/raptor_lake_s.dtsi:449 */
			gpio-controller;                 /* in zephyr/dts/x86/intel/raptor_lake_s.dtsi:450 */
			#gpio-cells = < 0x2 >;           /* in zephyr/dts/x86/intel/raptor_lake_s.dtsi:451 */
			ngpios = < 0x18 >;               /* in zephyr/dts/x86/intel/raptor_lake_s.dtsi:452 */
			pin-offset = < 0x20 >;           /* in zephyr/dts/x86/intel/raptor_lake_s.dtsi:453 */
			status = "okay";                 /* in zephyr/dts/x86/intel/raptor_lake_s.dtsi:455 */
		};

		/* node '/soc/gpio@e06b0790' defined in zephyr/dts/x86/intel/raptor_lake_s.dtsi:458 */
		gpio_3_a: gpio@e06b0790 {
			compatible = "intel,gpio";       /* in zephyr/dts/x86/intel/raptor_lake_s.dtsi:459 */
			reg = < 0xe06b0790 0x1000 >;     /* in zephyr/dts/x86/intel/raptor_lake_s.dtsi:460 */
			interrupts = < 0xe 0xa100 0x3 >; /* in zephyr/dts/x86/intel/raptor_lake_s.dtsi:461 */
			interrupt-parent = < &intc >;    /* in zephyr/dts/x86/intel/raptor_lake_s.dtsi:462 */
			group-index = < 0x1 >;           /* in zephyr/dts/x86/intel/raptor_lake_s.dtsi:463 */
			gpio-controller;                 /* in zephyr/dts/x86/intel/raptor_lake_s.dtsi:464 */
			#gpio-cells = < 0x2 >;           /* in zephyr/dts/x86/intel/raptor_lake_s.dtsi:465 */
			ngpios = < 0xf >;                /* in zephyr/dts/x86/intel/raptor_lake_s.dtsi:466 */
			pin-offset = < 0x9 >;            /* in zephyr/dts/x86/intel/raptor_lake_s.dtsi:467 */
			status = "okay";                 /* in zephyr/dts/x86/intel/raptor_lake_s.dtsi:469 */
		};

		/* node '/soc/gpio@e06b0890' defined in zephyr/dts/x86/intel/raptor_lake_s.dtsi:472 */
		gpio_3_c: gpio@e06b0890 {
			compatible = "intel,gpio";       /* in zephyr/dts/x86/intel/raptor_lake_s.dtsi:473 */
			reg = < 0xe06b0890 0x1000 >;     /* in zephyr/dts/x86/intel/raptor_lake_s.dtsi:474 */
			interrupts = < 0xe 0xa100 0x3 >; /* in zephyr/dts/x86/intel/raptor_lake_s.dtsi:475 */
			interrupt-parent = < &intc >;    /* in zephyr/dts/x86/intel/raptor_lake_s.dtsi:476 */
			group-index = < 0x2 >;           /* in zephyr/dts/x86/intel/raptor_lake_s.dtsi:477 */
			gpio-controller;                 /* in zephyr/dts/x86/intel/raptor_lake_s.dtsi:478 */
			#gpio-cells = < 0x2 >;           /* in zephyr/dts/x86/intel/raptor_lake_s.dtsi:479 */
			ngpios = < 0x18 >;               /* in zephyr/dts/x86/intel/raptor_lake_s.dtsi:480 */
			pin-offset = < 0x19 >;           /* in zephyr/dts/x86/intel/raptor_lake_s.dtsi:481 */
			status = "okay";                 /* in zephyr/dts/x86/intel/raptor_lake_s.dtsi:483 */
		};

		/* node '/soc/gpio@e06a0700' defined in zephyr/dts/x86/intel/raptor_lake_s.dtsi:486 */
		gpio_4_s: gpio@e06a0700 {
			compatible = "intel,gpio";       /* in zephyr/dts/x86/intel/raptor_lake_s.dtsi:487 */
			reg = < 0xe06a0700 0x1000 >;     /* in zephyr/dts/x86/intel/raptor_lake_s.dtsi:488 */
			interrupts = < 0xe 0xa100 0x3 >; /* in zephyr/dts/x86/intel/raptor_lake_s.dtsi:489 */
			interrupt-parent = < &intc >;    /* in zephyr/dts/x86/intel/raptor_lake_s.dtsi:490 */
			group-index = < 0x0 >;           /* in zephyr/dts/x86/intel/raptor_lake_s.dtsi:491 */
			gpio-controller;                 /* in zephyr/dts/x86/intel/raptor_lake_s.dtsi:492 */
			#gpio-cells = < 0x2 >;           /* in zephyr/dts/x86/intel/raptor_lake_s.dtsi:493 */
			ngpios = < 0x8 >;                /* in zephyr/dts/x86/intel/raptor_lake_s.dtsi:494 */
			pin-offset = < 0x0 >;            /* in zephyr/dts/x86/intel/raptor_lake_s.dtsi:495 */
			status = "okay";                 /* in zephyr/dts/x86/intel/raptor_lake_s.dtsi:497 */
		};

		/* node '/soc/gpio@e06a0780' defined in zephyr/dts/x86/intel/raptor_lake_s.dtsi:500 */
		gpio_4_e: gpio@e06a0780 {
			compatible = "intel,gpio";       /* in zephyr/dts/x86/intel/raptor_lake_s.dtsi:501 */
			reg = < 0xe06a0780 0x1000 >;     /* in zephyr/dts/x86/intel/raptor_lake_s.dtsi:502 */
			interrupts = < 0xe 0xa100 0x3 >; /* in zephyr/dts/x86/intel/raptor_lake_s.dtsi:503 */
			interrupt-parent = < &intc >;    /* in zephyr/dts/x86/intel/raptor_lake_s.dtsi:504 */
			group-index = < 0x1 >;           /* in zephyr/dts/x86/intel/raptor_lake_s.dtsi:505 */
			gpio-controller;                 /* in zephyr/dts/x86/intel/raptor_lake_s.dtsi:506 */
			#gpio-cells = < 0x2 >;           /* in zephyr/dts/x86/intel/raptor_lake_s.dtsi:507 */
			ngpios = < 0x16 >;               /* in zephyr/dts/x86/intel/raptor_lake_s.dtsi:508 */
			pin-offset = < 0x8 >;            /* in zephyr/dts/x86/intel/raptor_lake_s.dtsi:509 */
			status = "okay";                 /* in zephyr/dts/x86/intel/raptor_lake_s.dtsi:511 */
		};

		/* node '/soc/gpio@e06a08f0' defined in zephyr/dts/x86/intel/raptor_lake_s.dtsi:514 */
		gpio_4_k: gpio@e06a08f0 {
			compatible = "intel,gpio";       /* in zephyr/dts/x86/intel/raptor_lake_s.dtsi:515 */
			reg = < 0xe06a08f0 0x1000 >;     /* in zephyr/dts/x86/intel/raptor_lake_s.dtsi:516 */
			interrupts = < 0xe 0xa100 0x3 >; /* in zephyr/dts/x86/intel/raptor_lake_s.dtsi:517 */
			interrupt-parent = < &intc >;    /* in zephyr/dts/x86/intel/raptor_lake_s.dtsi:518 */
			group-index = < 0x2 >;           /* in zephyr/dts/x86/intel/raptor_lake_s.dtsi:519 */
			gpio-controller;                 /* in zephyr/dts/x86/intel/raptor_lake_s.dtsi:520 */
			#gpio-cells = < 0x2 >;           /* in zephyr/dts/x86/intel/raptor_lake_s.dtsi:521 */
			ngpios = < 0xc >;                /* in zephyr/dts/x86/intel/raptor_lake_s.dtsi:522 */
			pin-offset = < 0x19 >;           /* in zephyr/dts/x86/intel/raptor_lake_s.dtsi:523 */
			status = "okay";                 /* in zephyr/dts/x86/intel/raptor_lake_s.dtsi:525 */
		};

		/* node '/soc/gpio@e06a09e0' defined in zephyr/dts/x86/intel/raptor_lake_s.dtsi:528 */
		gpio_4_f: gpio@e06a09e0 {
			compatible = "intel,gpio";       /* in zephyr/dts/x86/intel/raptor_lake_s.dtsi:529 */
			reg = < 0xe06a09e0 0x1000 >;     /* in zephyr/dts/x86/intel/raptor_lake_s.dtsi:530 */
			interrupts = < 0xe 0xa100 0x3 >; /* in zephyr/dts/x86/intel/raptor_lake_s.dtsi:531 */
			interrupt-parent = < &intc >;    /* in zephyr/dts/x86/intel/raptor_lake_s.dtsi:532 */
			group-index = < 0x3 >;           /* in zephyr/dts/x86/intel/raptor_lake_s.dtsi:533 */
			gpio-controller;                 /* in zephyr/dts/x86/intel/raptor_lake_s.dtsi:534 */
			#gpio-cells = < 0x2 >;           /* in zephyr/dts/x86/intel/raptor_lake_s.dtsi:535 */
			ngpios = < 0x18 >;               /* in zephyr/dts/x86/intel/raptor_lake_s.dtsi:536 */
			pin-offset = < 0x29 >;           /* in zephyr/dts/x86/intel/raptor_lake_s.dtsi:537 */
			status = "okay";                 /* in zephyr/dts/x86/intel/raptor_lake_s.dtsi:539 */
		};

		/* node '/soc/gpio@e0690700' defined in zephyr/dts/x86/intel/raptor_lake_s.dtsi:542 */
		gpio_5_d: gpio@e0690700 {
			compatible = "intel,gpio";       /* in zephyr/dts/x86/intel/raptor_lake_s.dtsi:543 */
			reg = < 0xe0690700 0x1000 >;     /* in zephyr/dts/x86/intel/raptor_lake_s.dtsi:544 */
			interrupts = < 0xe 0xa100 0x3 >; /* in zephyr/dts/x86/intel/raptor_lake_s.dtsi:545 */
			interrupt-parent = < &intc >;    /* in zephyr/dts/x86/intel/raptor_lake_s.dtsi:546 */
			group-index = < 0x0 >;           /* in zephyr/dts/x86/intel/raptor_lake_s.dtsi:547 */
			gpio-controller;                 /* in zephyr/dts/x86/intel/raptor_lake_s.dtsi:548 */
			#gpio-cells = < 0x2 >;           /* in zephyr/dts/x86/intel/raptor_lake_s.dtsi:549 */
			ngpios = < 0x18 >;               /* in zephyr/dts/x86/intel/raptor_lake_s.dtsi:550 */
			pin-offset = < 0x0 >;            /* in zephyr/dts/x86/intel/raptor_lake_s.dtsi:551 */
			status = "okay";                 /* in zephyr/dts/x86/intel/raptor_lake_s.dtsi:553 */
		};

		/* node '/soc/pwm@e06a0000' defined in zephyr/dts/x86/intel/raptor_lake_s.dtsi:556 */
		pwm0: pwm@e06a0000 {
			compatible = "intel,blinky-pwm"; /* in zephyr/dts/x86/intel/raptor_lake_s.dtsi:557 */
			reg = < 0xe06a0000 0x400 >;      /* in zephyr/dts/x86/intel/raptor_lake_s.dtsi:558 */
			reg-offset = < 0x304 >;          /* in zephyr/dts/x86/intel/raptor_lake_s.dtsi:559 */
			clock-frequency = < 0x8000 >;    /* in zephyr/dts/x86/intel/raptor_lake_s.dtsi:560 */
			max-pins = < 0x1 >;              /* in zephyr/dts/x86/intel/raptor_lake_s.dtsi:561 */
			#pwm-cells = < 0x2 >;            /* in zephyr/dts/x86/intel/raptor_lake_s.dtsi:562 */
			status = "okay";                 /* in zephyr/dts/x86/intel/raptor_lake_s.dtsi:563 */
		};

		/* node '/soc/mfd@70' defined in zephyr/dts/x86/intel/raptor_lake_s.dtsi:566 */
		mfd: mfd@70 {
			compatible = "motorola,mc146818-mfd";          /* in zephyr/dts/x86/intel/raptor_lake_s.dtsi:567 */
			reg = < 0x70 0x1 0x71 0x1 0x72 0x1 0x73 0x1 >; /* in zephyr/dts/x86/intel/raptor_lake_s.dtsi:568 */
			status = "okay";                               /* in zephyr/dts/x86/intel/raptor_lake_s.dtsi:585 */

			/* node '/soc/mfd@70/rtc' defined in zephyr/dts/x86/intel/raptor_lake_s.dtsi:570 */
			rtc: counter: rtc {
				compatible = "motorola,mc146818"; /* in zephyr/dts/x86/intel/raptor_lake_s.dtsi:571 */
				interrupts = < 0x8 0x100 0x3 >;   /* in zephyr/dts/x86/intel/raptor_lake_s.dtsi:572 */
				interrupt-parent = < &intc >;     /* in zephyr/dts/x86/intel/raptor_lake_s.dtsi:573 */
				alarms-count = < 0x1 >;           /* in zephyr/dts/x86/intel/raptor_lake_s.dtsi:574 */
				status = "okay";                  /* in zephyr/dts/x86/intel/raptor_lake_s.dtsi:576 */
			};

			/* node '/soc/mfd@70/bbram' defined in zephyr/dts/x86/intel/raptor_lake_s.dtsi:579 */
			bbram: bbram {
				compatible = "motorola,mc146818-bbram"; /* in zephyr/dts/x86/intel/raptor_lake_s.dtsi:580 */
				size = < 0xf1 >;                        /* in zephyr/dts/x86/intel/raptor_lake_s.dtsi:581 */
				status = "okay";                        /* in zephyr/dts/x86/intel/raptor_lake_s.dtsi:582 */
			};
		};

		/* node '/soc/tgpio@fe001200' defined in zephyr/dts/x86/intel/raptor_lake_s.dtsi:588 */
		tgpio: tgpio@fe001200 {
			compatible = "intel,timeaware-gpio"; /* in zephyr/dts/x86/intel/raptor_lake_s.dtsi:589 */
			reg = < 0xfe001200 0x100 >;          /* in zephyr/dts/x86/intel/raptor_lake_s.dtsi:590 */
			timer-clock = < 0x124f800 >;         /* in zephyr/dts/x86/intel/raptor_lake_s.dtsi:591 */
			max-pins = < 0x2 >;                  /* in zephyr/dts/x86/intel/raptor_lake_s.dtsi:592 */
			status = "okay";                     /* in zephyr/dts/x86/intel/raptor_lake_s.dtsi:593 */
		};

		/* node '/soc/hpet@fed00000' defined in zephyr/dts/x86/intel/raptor_lake_s.dtsi:596 */
		hpet: hpet@fed00000 {
			compatible = "intel,hpet";    /* in zephyr/dts/x86/intel/raptor_lake_s.dtsi:597 */
			reg = < 0xfed00000 0x400 >;   /* in zephyr/dts/x86/intel/raptor_lake_s.dtsi:598 */
			interrupts = < 0x2 0x0 0x4 >; /* in zephyr/dts/x86/intel/raptor_lake_s.dtsi:599 */
			interrupt-parent = < &intc >; /* in zephyr/dts/x86/intel/raptor_lake_s.dtsi:600 */
			status = "okay";              /* in zephyr/dts/x86/intel/raptor_lake_s.dtsi:602 */
		};

		/* node '/soc/tco_wdt@400' defined in zephyr/dts/x86/intel/raptor_lake_s.dtsi:605 */
		tco_wdt: tco_wdt@400 {
			compatible = "intel,tco-wdt"; /* in zephyr/dts/x86/intel/raptor_lake_s.dtsi:606 */
			reg = < 0x400 0x20 >;         /* in zephyr/dts/x86/intel/raptor_lake_s.dtsi:607 */
			status = "disabled";          /* in zephyr/dts/x86/intel/raptor_lake_s.dtsi:609 */
		};
	};
};
